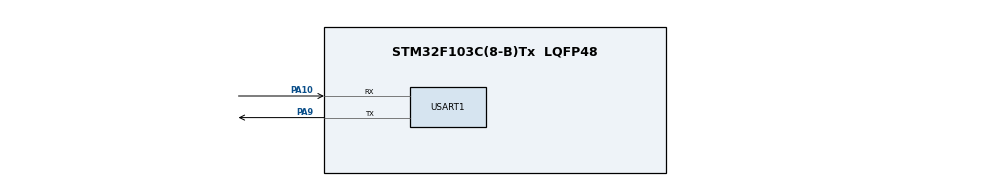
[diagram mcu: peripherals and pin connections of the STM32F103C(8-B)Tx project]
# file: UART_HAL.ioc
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Mcu.Family=STM32F1
Mcu.Name=STM32F103C(8-B)Tx
Mcu.Package=LQFP48
NVIC.PriorityGroup=NVIC_PRIORITYGROUP_4
NVIC.USART1_IRQn=true\:0\:0\:false\:false\:true\:true\:true\:true
PA10.Mode=Asynchronous
PA10.Signal=USART1_RX
PA9.Mode=Asynchronous
PA9.Signal=USART1_TX
ProjectManager.HeapSize=0x200
ProjectManager.StackSize=0x400
ProjectManager.TargetToolchain=MDK-ARM V5.32
RCC.APB1Freq_Value=8000000
RCC.APB2Freq_Value=8000000
USART1.VirtualMode=VM_ASYNC
VP_SYS_VS_ND.Mode=No_Debug
board=custom

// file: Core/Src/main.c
/* USER CODE BEGIN Header */
/**
  ******************************************************************************
  * @file           : main.c
  * @brief          : Main program body
  ******************************************************************************
  * @attention
  *
  * Copyright (c) 2023 STMicroelectronics.
  * All rights reserved.
  *
  * This software is licensed under terms that can be found in the LICENSE file
  * in the root directory of this software component.
  * If no LICENSE file comes with this software, it is provided AS-IS.
  *
  ******************************************************************************
  */
/* USER CODE END Header */
#include "main.h"

/* USER CODE BEGIN Includes */
	uint8_t u8_RxBuff[20];
	uint8_t u8_RxData;
	uint8_t u8_TxBuff[20]="hello anh em\n";
	uint8_t _rxIndex;
	uint16_t Tx_Flag=0;
/* USER CODE END Includes */

UART_HandleTypeDef huart1;

void SystemClock_Config(void);
static void MX_GPIO_Init(void);
static void MX_USART1_UART_Init(void);

/* USER CODE BEGIN 0 */
 void HAL_UART_RxCpltCallback(UART_HandleTypeDef *huart)
{
  /* Prevent unused argument(s) compilation warning */
  UNUSED(huart);
	if( huart->Instance==USART1)
	{
		if(u8_RxData!=13) u8_RxBuff[_rxIndex++] =u8_RxData;
		else if (u8_RxData==13){
			_rxIndex=0;// xoa con tro du lieu
			Tx_Flag=1;
		}
		HAL_UART_Receive_IT(&huart,&u8_RxData,1);
	}
  /* NOTE: This function should not be modified, when the callback is needed,
           the HAL_UART_RxCpltCallback could be implemented in the user file
   */
}

/* USER CODE END 0 */

int main(void)
{

  /* MCU Configuration--------------------------------------------------------*/

  /* Reset of all peripherals, Initializes the Flash interface and the Systick. */
  HAL_Init();

  /* Configure the system clock */
  SystemClock_Config();

  /* Initialize all configured peripherals */
  MX_GPIO_Init();
  MX_USART1_UART_Init();
  /* USER CODE BEGIN 2 */
HAL_UART_Transmit(&huart1, u8_TxBuff, sizeof(u8_TxBuff),100);

  /* USER CODE END 2 */

  /* Infinite loop */
  /* USER CODE BEGIN WHILE */
  while (1)
  {
		HAL_UART_Receive_IT(&huart1, &u8_RxData,1);
    /* USER CODE END WHILE */

    /* USER CODE BEGIN 3 */

		if(Tx_Flag){

			for(int i=0; i<20; i++)// copy du lieu tu rx sang tx
			{
				u8_TxBuff[i]=u8_RxBuff[i];
			}
			HAL_UART_Transmit(&huart1, u8_TxBuff, sizeof(u8_TxBuff),100);
			Tx_Flag=0;
		}
  }
  /* USER CODE END 3 */
}

void SystemClock_Config(void)
{
  RCC_OscInitTypeDef RCC_OscInitStruct = {0};
  RCC_ClkInitTypeDef RCC_ClkInitStruct = {0};

  /** Initializes the RCC Oscillators according to the specified parameters
  * in the RCC_OscInitTypeDef structure.
  */
  RCC_OscInitStruct.OscillatorType = RCC_OSCILLATORTYPE_HSI;
  RCC_OscInitStruct.HSIState = RCC_HSI_ON;
  RCC_OscInitStruct.HSICalibrationValue = RCC_HSICALIBRATION_DEFAULT;
  RCC_OscInitStruct.PLL.PLLState = RCC_PLL_NONE;
  if (HAL_RCC_OscConfig(&RCC_OscInitStruct) != HAL_OK)
  {
    Error_Handler();
  }

  /** Initializes the CPU, AHB and APB buses clocks
  */
  RCC_ClkInitStruct.ClockType = RCC_CLOCKTYPE_HCLK|RCC_CLOCKTYPE_SYSCLK
                              |RCC_CLOCKTYPE_PCLK1|RCC_CLOCKTYPE_PCLK2;
  RCC_ClkInitStruct.SYSCLKSource = RCC_SYSCLKSOURCE_HSI;
  RCC_ClkInitStruct.AHBCLKDivider = RCC_SYSCLK_DIV1;
  RCC_ClkInitStruct.APB1CLKDivider = RCC_HCLK_DIV1;
  RCC_ClkInitStruct.APB2CLKDivider = RCC_HCLK_DIV1;

  if (HAL_RCC_ClockConfig(&RCC_ClkInitStruct, FLASH_LATENCY_0) != HAL_OK)
  {
    Error_Handler();
  }
}

static void MX_USART1_UART_Init(void)
{

  huart1.Instance = USART1;
  huart1.Init.BaudRate = 9600;
  huart1.Init.WordLength = UART_WORDLENGTH_8B;
  huart1.Init.StopBits = UART_STOPBITS_1;
  huart1.Init.Parity = UART_PARITY_NONE;
  huart1.Init.Mode = UART_MODE_TX_RX;
  huart1.Init.HwFlowCtl = UART_HWCONTROL_NONE;
  huart1.Init.OverSampling = UART_OVERSAMPLING_16;
  if (HAL_UART_Init(&huart1) != HAL_OK)
  {
    Error_Handler();
  }

}

static void MX_GPIO_Init(void)
{

  /* GPIO Ports Clock Enable */
  __HAL_RCC_GPIOA_CLK_ENABLE();

}

void Error_Handler(void)
{
  __disable_irq();
  while (1)
  {
  }
}
